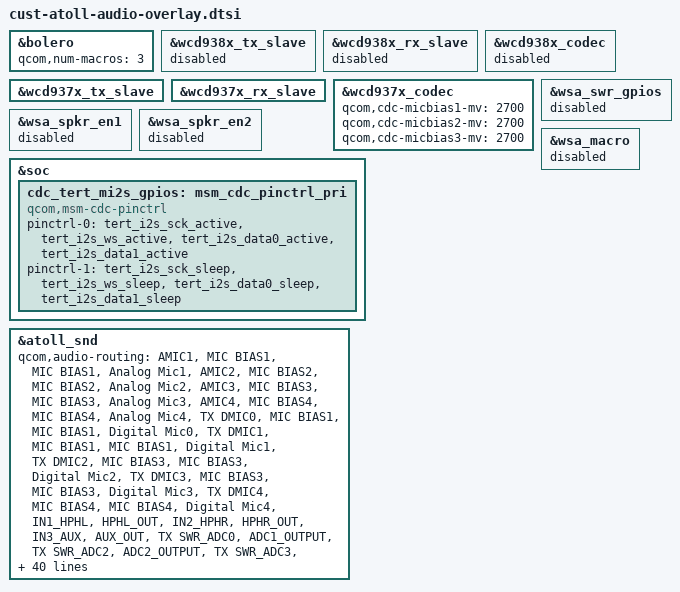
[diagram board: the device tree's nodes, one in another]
&bolero {
	qcom,num-macros = <3>;
};

&wcd938x_tx_slave {
	status = "disabled";
};

&wcd938x_rx_slave {
	status = "disabled";
};

&wcd938x_codec {
	status = "disabled";
};

&wcd937x_tx_slave {
	status = "okay";
};

&wcd937x_rx_slave {
	status = "okay";
};

&wcd937x_codec {
	status = "okay";

	qcom,cdc-micbias1-mv = <2700>;
	qcom,cdc-micbias2-mv = <2700>;
	qcom,cdc-micbias3-mv = <2700>;
};

&wsa_swr_gpios {
	status = "disabled";
};

&wsa_spkr_en1 {
	status = "disabled";
};

&wsa_spkr_en2 {
	status = "disabled";
};

&wsa_macro {
	status = "disabled";
};

&soc {
	cdc_tert_mi2s_gpios: msm_cdc_pinctrl_pri {
		compatible = "qcom,msm-cdc-pinctrl";
		pinctrl-names = "aud_active", "aud_sleep";
		pinctrl-0 = <&tert_i2s_sck_active &tert_i2s_ws_active
				&tert_i2s_data0_active &tert_i2s_data1_active>;
		pinctrl-1 = <&tert_i2s_sck_sleep &tert_i2s_ws_sleep
				&tert_i2s_data0_sleep &tert_i2s_data1_sleep>;
	};	
};

&atoll_snd {
	qcom,audio-routing =
		"AMIC1", "MIC BIAS1",
		"MIC BIAS1", "Analog Mic1",
		"AMIC2", "MIC BIAS2",
		"MIC BIAS2", "Analog Mic2",
		"AMIC3", "MIC BIAS3",
		"MIC BIAS3", "Analog Mic3",
		"AMIC4", "MIC BIAS4",
		"MIC BIAS4", "Analog Mic4",
		"TX DMIC0", "MIC BIAS1",
		"MIC BIAS1", "Digital Mic0",
		"TX DMIC1", "MIC BIAS1",
		"MIC BIAS1", "Digital Mic1",
		"TX DMIC2", "MIC BIAS3",
		"MIC BIAS3", "Digital Mic2",
		"TX DMIC3", "MIC BIAS3",
		"MIC BIAS3", "Digital Mic3",
		"TX DMIC4", "MIC BIAS4",
		"MIC BIAS4", "Digital Mic4",
		"IN1_HPHL", "HPHL_OUT",
		"IN2_HPHR", "HPHR_OUT",
		"IN3_AUX", "AUX_OUT",
		"TX SWR_ADC0", "ADC1_OUTPUT",
		"TX SWR_ADC2", "ADC2_OUTPUT",
		"TX SWR_ADC3", "ADC3_OUTPUT",
		"TX SWR_DMIC0", "DMIC1_OUTPUT",
		"TX SWR_DMIC1", "DMIC2_OUTPUT",
		"TX SWR_DMIC2", "DMIC3_OUTPUT",
		"TX SWR_DMIC3", "DMIC4_OUTPUT",
		"TX SWR_DMIC4", "DMIC5_OUTPUT",
		"TX SWR_DMIC5", "DMIC6_OUTPUT",
		"TX SWR_DMIC6", "DMIC7_OUTPUT",
		"TX SWR_DMIC7", "DMIC8_OUTPUT",
		"WSA SRC0_INP", "SRC0",
		"WSA_TX DEC0_INP", "TX DEC0 MUX",
		"WSA_TX DEC1_INP", "TX DEC1 MUX",
		"RX_TX DEC0_INP", "TX DEC0 MUX",
		"RX_TX DEC1_INP", "TX DEC1 MUX",
		"RX_TX DEC2_INP", "TX DEC2 MUX",
		"RX_TX DEC3_INP", "TX DEC3 MUX",
		"SpkrLeft IN", "WSA_SPK1 OUT",
		"SpkrRight IN", "WSA_SPK2 OUT",
		"VA_AIF1 CAP", "VA_SWR_CLK",
		"VA_AIF2 CAP", "VA_SWR_CLK",
		"VA_AIF3 CAP", "VA_SWR_CLK",
		"VA MIC BIAS1", "Digital Mic0",
		"VA MIC BIAS1", "Digital Mic1",
		"VA MIC BIAS3", "Digital Mic2",
		"VA MIC BIAS3", "Digital Mic3",
		"VA MIC BIAS4", "Digital Mic4",
		"VA DMIC0", "VA MIC BIAS1",
		"VA DMIC1", "VA MIC BIAS1",
		"VA DMIC2", "VA MIC BIAS3",
		"VA DMIC3", "VA MIC BIAS3",
		"VA DMIC4", "VA MIC BIAS4",
		"VA SWR_ADC0", "VA_SWR_CLK",
		"VA SWR_ADC1", "VA_SWR_CLK",
		"VA SWR_ADC2", "VA_SWR_CLK",
		"VA SWR_ADC3", "VA_SWR_CLK",
		"VA SWR_MIC0", "VA_SWR_CLK",
		"VA SWR_MIC1", "VA_SWR_CLK",
		"VA SWR_MIC2", "VA_SWR_CLK",
		"VA SWR_MIC3", "VA_SWR_CLK",
		"VA SWR_MIC4", "VA_SWR_CLK",
		"VA SWR_MIC5", "VA_SWR_CLK",
		"VA SWR_MIC6", "VA_SWR_CLK",
		"VA SWR_MIC7", "VA_SWR_CLK",
		"VA SWR_ADC0", "ADC1_OUTPUT",
		"VA SWR_ADC1", "ADC2_OUTPUT",
		"VA SWR_ADC2", "ADC3_OUTPUT",
		"VA SWR_ADC3", "ADC4_OUTPUT",
		"VA SWR_MIC0", "DMIC1_OUTPUT",
		"VA SWR_MIC1", "DMIC2_OUTPUT",
		"VA SWR_MIC2", "DMIC3_OUTPUT",
		"VA SWR_MIC3", "DMIC4_OUTPUT",
		"VA SWR_MIC4", "DMIC5_OUTPUT",
		"VA SWR_MIC5", "DMIC6_OUTPUT",
		"VA SWR_MIC6", "DMIC7_OUTPUT",
		"VA SWR_MIC7", "DMIC8_OUTPUT";

	qcom,wsa-max-devs = <0>;
	qcom,codec-aux-devs = <&wcd937x_codec>;
	qcom,tert-mi2s-gpios = <&cdc_tert_mi2s_gpios>;
};
